VERSION ""

NS_ :

BS_:

BU_: DCDC_2 HV_PDU_1 VCU

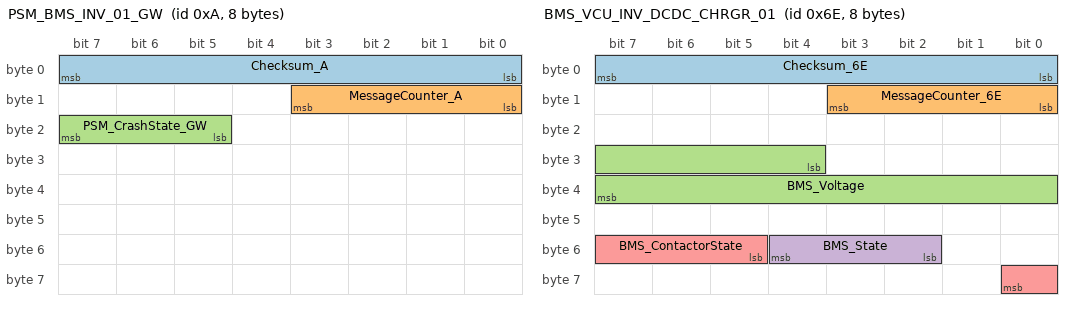
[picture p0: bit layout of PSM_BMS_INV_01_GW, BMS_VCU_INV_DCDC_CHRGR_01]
BO_ 10 PSM_BMS_INV_01_GW: 8 VCU
  SG_ Checksum_A : 0|8@1+ (1,0) [0|255] "NoUnit" DCDC_2
  SG_ MessageCounter_A : 8|4@1+ (1,0) [0|15] "NoUnit" DCDC_2
  SG_ PSM_CrashState_GW : 21|3@1+ (1,0) [0|7] "NoUnit" DCDC_2

BO_ 110 BMS_VCU_INV_DCDC_CHRGR_01: 8 VCU
  SG_ Checksum_6E : 0|8@1+ (1,0) [0|255] "NoUnit" DCDC_2
  SG_ MessageCounter_6E : 8|4@1+ (1,0) [0|15] "NoUnit" DCDC_2
  SG_ BMS_Voltage : 28|12@1+ (0.25,0) [0|1023.25] "V" DCDC_2
  SG_ BMS_State : 50|3@1+ (1,0) [0|7] "NoUnit" DCDC_2
  SG_ BMS_ContactorState : 53|4@1+ (1,0) [0|15] "NoUnit" DCDC_2

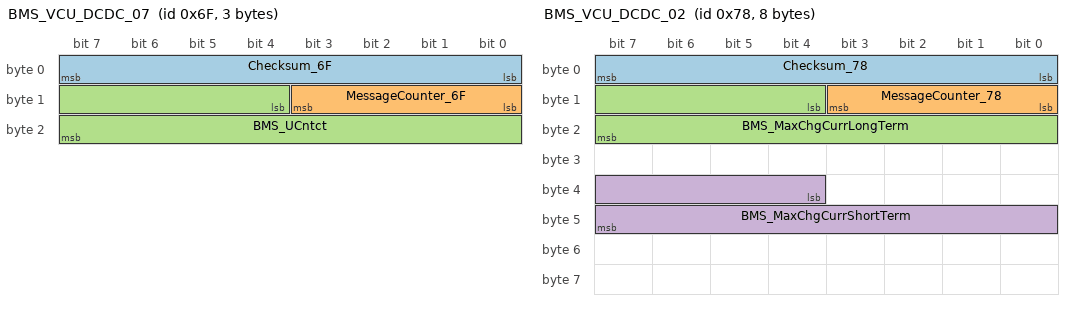
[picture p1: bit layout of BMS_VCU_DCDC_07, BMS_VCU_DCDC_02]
BO_ 111 BMS_VCU_DCDC_07: 3 VCU
  SG_ Checksum_6F : 0|8@1+ (1,0) [0|255] "NoUnit" DCDC_2
  SG_ MessageCounter_6F : 8|4@1+ (1,0) [0|15] "NoUnit" DCDC_2
  SG_ BMS_UCntct : 12|12@1+ (0.25,0) [0|1023.25] "V" DCDC_2

BO_ 120 BMS_VCU_DCDC_02: 8 VCU
  SG_ Checksum_78 : 0|8@1+ (1,0) [0|255] "NoUnit" DCDC_2
  SG_ MessageCounter_78 : 8|4@1+ (1,0) [0|15] "NoUnit" DCDC_2
  SG_ BMS_MaxChgCurrLongTerm : 12|12@1+ (1,0) [0|4094] "A" DCDC_2
  SG_ BMS_MaxChgCurrShortTerm : 36|12@1+ (1,0) [0|4094] "A" DCDC_2

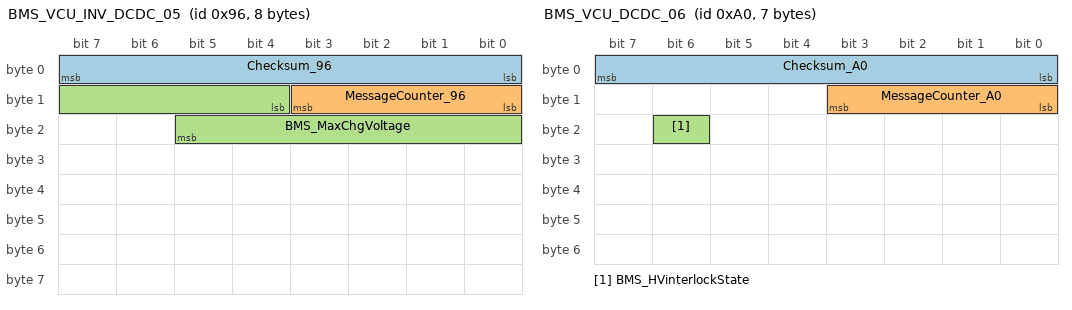
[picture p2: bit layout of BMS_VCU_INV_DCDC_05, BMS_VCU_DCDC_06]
BO_ 150 BMS_VCU_INV_DCDC_05: 8 VCU
  SG_ Checksum_96 : 0|8@1+ (1,0) [0|255] "NoUnit" DCDC_2
  SG_ MessageCounter_96 : 8|4@1+ (1,0) [0|15] "NoUnit" DCDC_2
  SG_ BMS_MaxChgVoltage : 12|10@1+ (1,0) [0|1021] "V" DCDC_2

BO_ 160 BMS_VCU_DCDC_06: 7 VCU
  SG_ Checksum_A0 : 0|8@1+ (1,0) [0|255] "NoUnit" DCDC_2
  SG_ MessageCounter_A0 : 8|4@1+ (1,0) [0|15] "NoUnit" DCDC_2
  SG_ BMS_HVinterlockState : 22|1@1+ (1,0) [0|1] "NoUnit" DCDC_2

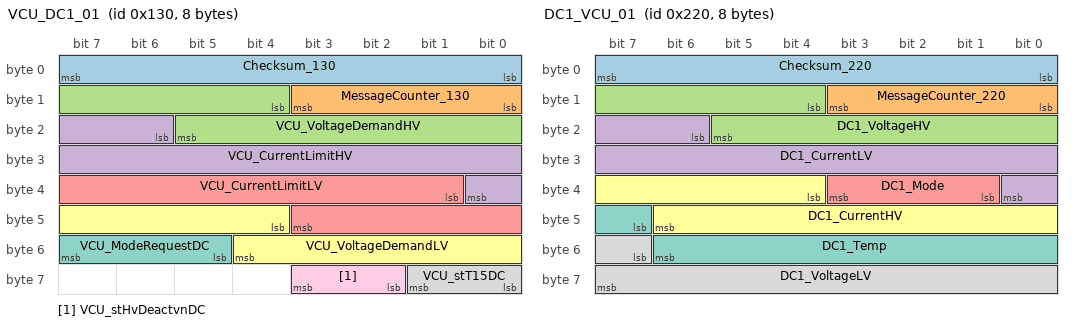
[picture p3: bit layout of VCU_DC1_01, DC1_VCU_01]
BO_ 304 VCU_DC1_01: 8 VCU
  SG_ Checksum_130 : 0|8@1+ (1,0) [0|255] "NoUnit" DCDC_2
  SG_ MessageCounter_130 : 8|4@1+ (1,0) [0|15] "NoUnit" DCDC_2
  SG_ VCU_VoltageDemandHV : 12|10@1+ (1,0) [0|1021] "V" DCDC_2
  SG_ VCU_CurrentLimitHV : 22|11@1+ (0.0625,-64) [-64|63.8125] "A" DCDC_2
  SG_ VCU_CurrentLimitLV : 33|11@1+ (1,-1023) [-1023|1022] "A" DCDC_2
  SG_ VCU_VoltageDemandLV : 44|9@1+ (0.125,0) [0|63.625] "V" DCDC_2
  SG_ VCU_ModeRequestDC : 53|3@1+ (1,0) [0|7] "NoUnit" DCDC_2
  SG_ VCU_stT15DC : 56|2@1+ (1,0) [0|1] "NoUnit" DCDC_2
  SG_ VCU_stHvDeactvnDC : 58|2@1+ (1,0) [0|3] "NoUnit" DCDC_2

BO_ 514 XCP_Response_Ivt: 8 HV_PDU_1
  SG_ XCP_Buffer_TxIvt : 0|64@1- (1,0) [0|0] "NoUnit" VCU

BO_ 544 DC1_VCU_01: 8 DCDC_2
  SG_ Checksum_220 : 0|8@1+ (1,0) [0|255] "NoUnit" VCU
  SG_ MessageCounter_220 : 8|4@1+ (1,0) [0|15] "NoUnit" VCU
  SG_ DC1_VoltageHV : 12|10@1+ (1,0) [0|1021] "V" VCU
  SG_ DC1_CurrentLV : 22|11@1+ (1,-1023) [-1023|1022] "A" VCU
  SG_ DC1_Mode : 33|3@1+ (1,0) [0|7] "NoUnit" VCU
  SG_ DC1_CurrentHV : 36|11@1+ (0.0625,-63.90625) [-63.90625|63.90625] "A" VCU
  SG_ DC1_Temp : 47|8@1+ (1,-40) [-40|213] "°C" VCU
  SG_ DC1_VoltageLV : 55|9@1+ (0.125,0) [0|63.625] "V" VCU

BO_ 770 UDS_Response_Ivt: 8 HV_PDU_1
  SG_ UDS_Buffer_TxIvt : 0|64@1- (1,0) [0|0] "NoUnit" VCU

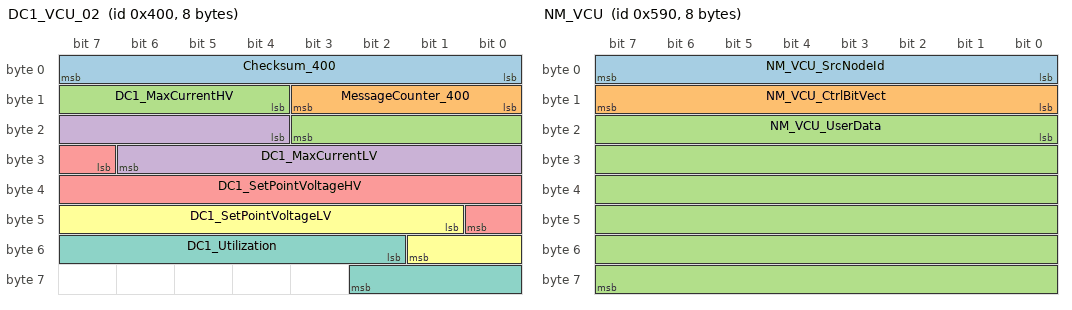
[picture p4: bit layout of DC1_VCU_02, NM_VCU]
BO_ 1024 DC1_VCU_02: 8 DCDC_2
  SG_ Checksum_400 : 0|8@1+ (1,0) [0|255] "NoUnit" VCU
  SG_ MessageCounter_400 : 8|4@1+ (1,0) [0|15] "NoUnit" VCU
  SG_ DC1_MaxCurrentHV : 12|8@1+ (0.25,0) [0|63.75] "A" VCU
  SG_ DC1_MaxCurrentLV : 20|11@1+ (1,-1023) [-1023|1024] "A" VCU
  SG_ DC1_SetPointVoltageHV : 31|10@1+ (1,0) [0|1023] "V" VCU
  SG_ DC1_SetPointVoltageLV : 41|9@1+ (0.125,0) [0|63.875] "V" VCU
  SG_ DC1_Utilization : 50|9@1+ (0.25,0) [0|127.75] "%" VCU

BO_ 1040 DC1_VCU_03: 4 DCDC_2
  SG_ Checksum_410 : 0|8@1+ (1,0) [0|255] "NoUnit" VCU
  SG_ MessageCounter_410 : 8|4@1+ (1,0) [0|15] "NoUnit" VCU
  SG_ DC1_bDernUndrUdcLv : 12|1@1+ (1,0) [0|1] "NoUnit" VCU
  SG_ DC1_bDernOvrUdcLv : 13|1@1+ (1,0) [0|1] "NoUnit" VCU
  SG_ DC1_bDernUndrUdcHv : 14|1@1+ (1,0) [0|1] "NoUnit" VCU
  SG_ DC1_bDernOvrUdcHv : 15|1@1+ (1,0) [0|1] "NoUnit" VCU
  SG_ DC1_bDernTemp_DCDC : 18|1@1+ (1,0) [0|1] "NoUnit" VCU
  SG_ DC1_ErrLimitedPerformance : 19|1@1+ (1,0) [0|1] "NoUnit" VCU
  SG_ DC1_bErrVltg : 20|1@1+ (1,0) [0|1] "NoUnit" VCU
  SG_ DC1_ErrShtOff : 21|1@1+ (1,0) [0|1] "NoUnit" VCU
  SG_ DC1_bErrCrashDetd : 22|1@1+ (1,0) [0|1] "NoUnit" VCU
  SG_ DC1_bErrLvBattOutOfRng : 23|1@1+ (1,0) [0|1] "NoUnit" VCU
  SG_ DC1_bErrHvLineOutOfRng : 24|1@1+ (1,0) [0|1] "NoUnit" VCU
  SG_ DC1_bErrHvIllegalCurrent : 25|1@1+ (1,0) [0|1] "NoUnit" VCU
  SG_ DC1_bErrHvSpNotReachedTimeout : 26|1@1+ (1,0) [0|1] "NoUnit" VCU
  SG_ DC1_bErrCanMsg : 27|1@1+ (1,0) [0|1] "NoUnit" VCU
  SG_ DC1_bPrecCmpl : 28|1@1+ (1,0) [0|1] "NoUnit" VCU
  SG_ DC1_bReqMIL : 29|1@1+ (1,0) [0|1] "NoUnit" VCU
  SG_ DC1_stT30c : 30|2@1+ (1,0) [0|3] "NoUnit" VCU

BO_ 1424 NM_VCU: 8 VCU
  SG_ NM_VCU_SrcNodeId : 0|8@1+ (1,0) [0|255] "NoUnit" DCDC_2
  SG_ NM_VCU_CtrlBitVect : 8|8@1+ (1,0) [0|255] "NoUnit" DCDC_2
  SG_ NM_VCU_UserData : 16|48@1+ (1,0) [0|0] "NoUnit" DCDC_2

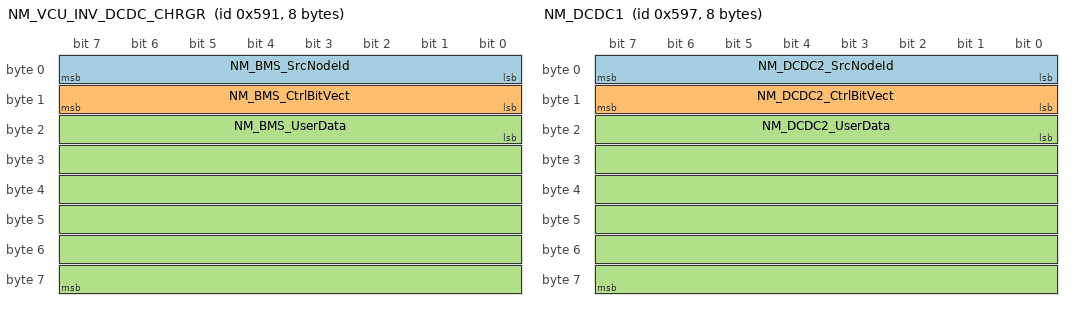
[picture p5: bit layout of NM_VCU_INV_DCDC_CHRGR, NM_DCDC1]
BO_ 1425 NM_VCU_INV_DCDC_CHRGR: 8 VCU
  SG_ NM_BMS_SrcNodeId : 0|8@1+ (1,0) [0|255] "NoUnit" DCDC_2
  SG_ NM_BMS_CtrlBitVect : 8|8@1+ (1,0) [0|255] "NoUnit" DCDC_2
  SG_ NM_BMS_UserData : 16|48@1+ (1,0) [0|0] "NoUnit" DCDC_2

BO_ 1431 NM_DCDC1: 8 DCDC_2
  SG_ NM_DCDC2_SrcNodeId : 0|8@1+ (1,0) [0|255] "NoUnit" VCU
  SG_ NM_DCDC2_CtrlBitVect : 8|8@1+ (1,0) [0|255] "NoUnit" VCU
  SG_ NM_DCDC2_UserData : 16|48@1+ (1,0) [0|0] "NoUnit" VCU

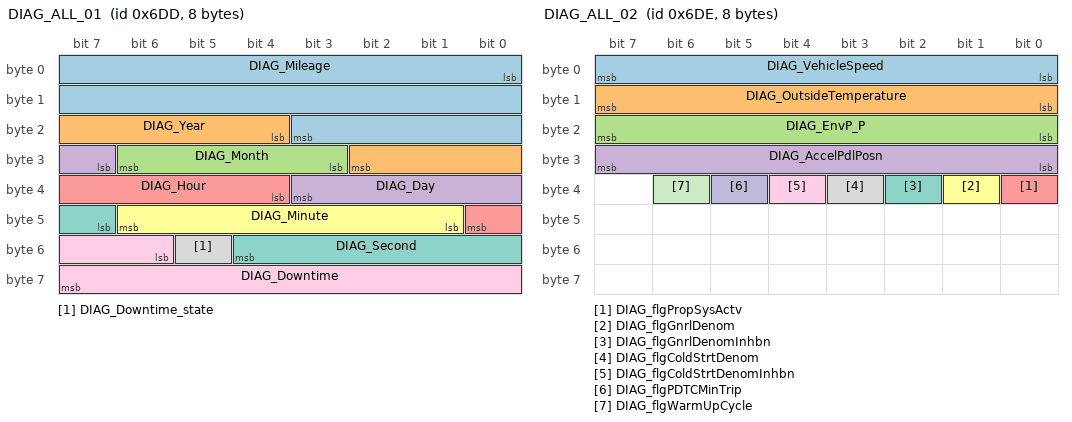
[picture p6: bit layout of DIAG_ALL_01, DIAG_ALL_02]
BO_ 1757 DIAG_ALL_01: 8 VCU
  SG_ DIAG_Mileage : 0|20@1+ (1,0) [0|1048575] "Km" DCDC_2
  SG_ DIAG_Year : 20|7@1+ (1,2000) [2000|2127] "year" DCDC_2
  SG_ DIAG_Month : 27|4@1+ (1,0) [1|12] "month" DCDC_2
  SG_ DIAG_Day : 31|5@1+ (1,0) [1|31] "day" DCDC_2
  SG_ DIAG_Hour : 36|5@1+ (1,0) [0|23] "h" DCDC_2
  SG_ DIAG_Minute : 41|6@1+ (1,0) [0|59] "NoUnit" DCDC_2
  SG_ DIAG_Second : 47|6@1+ (1,0) [0|59] "s" DCDC_2
  SG_ DIAG_Downtime_state : 53|1@1+ (1,0) [0|1] "NoUnit" DCDC_2
  SG_ DIAG_Downtime : 54|10@1+ (32,0) [0|32736] "s" DCDC_2

BO_ 1758 DIAG_ALL_02: 8 VCU
  SG_ DIAG_VehicleSpeed : 0|8@1+ (1,0) [0|255] "KMPH" DCDC_2
  SG_ DIAG_OutsideTemperature : 8|8@1+ (1,-40) [-40|213] "°C" DCDC_2
  SG_ DIAG_EnvP_P : 16|8@1+ (7.8,0) [0|1973.4] "hPa" DCDC_2
  SG_ DIAG_AccelPdlPosn : 24|8@1+ (0.5,0) [0|100] "%" DCDC_2
  SG_ DIAG_flgPropSysActv : 32|1@1+ (1,0) [0|1] "NoUnit" DCDC_2
  SG_ DIAG_flgGnrlDenom : 33|1@1+ (1,0) [0|1] "NoUnit" DCDC_2
  SG_ DIAG_flgGnrlDenomInhbn : 34|1@1+ (1,0) [0|1] "NoUnit" DCDC_2
  SG_ DIAG_flgColdStrtDenom : 35|1@1+ (1,0) [0|1] "NoUnit" DCDC_2
  SG_ DIAG_flgColdStrtDenomInhbn : 36|1@1+ (1,0) [0|1] "NoUnit" DCDC_2
  SG_ DIAG_flgPDTCMinTrip : 37|1@1+ (1,0) [0|1] "NoUnit" DCDC_2
  SG_ DIAG_flgWarmUpCycle : 38|1@1+ (1,0) [0|1] "NoUnit" DCDC_2

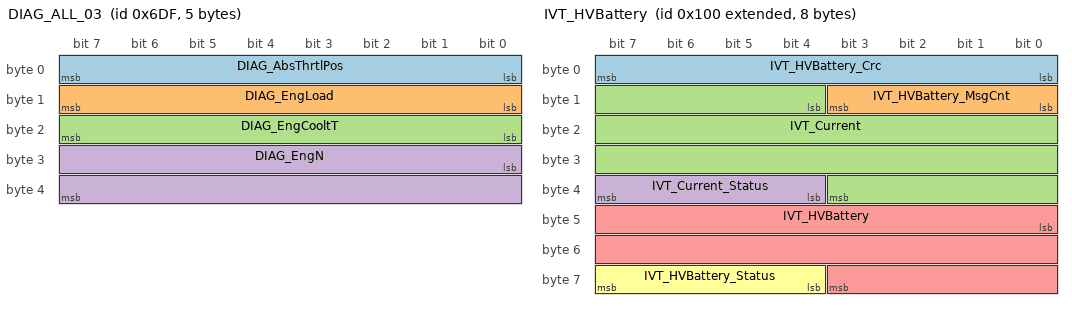
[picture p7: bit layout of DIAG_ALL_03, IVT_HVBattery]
BO_ 1759 DIAG_ALL_03: 5 VCU
  SG_ DIAG_AbsThrtlPos : 0|8@1+ (0.392157,0) [0|100.000035] "%" DCDC_2
  SG_ DIAG_EngLoad : 8|8@1+ (0.392157,0) [0|100.000035] "%" DCDC_2
  SG_ DIAG_EngCooltT : 16|8@1+ (1,-40) [-40|215] "°C" DCDC_2
  SG_ DIAG_EngN : 24|16@1+ (0.25,0) [0|16383.25] "1/min" DCDC_2

BO_ 1792 DIAG_REQUEST_FUNC: 8 VCU
  SG_ N_PDU_RQ_FUNC : 0|64@1+ (1,0) [0|0] "NoUnit" DCDC_2

BO_ 2015 DIAG_REQUEST_OBD: 8 VCU
  SG_ N_PDU_RQ_OBD : 0|64@1+ (1,0) [0|0] "NoUnit" DCDC_2

BO_ 2019 DIAG_REQUEST_DC1: 8 VCU
  SG_ N_PDU_RQ_DC1 : 0|64@1+ (1,0) [0|0] "NoUnit" DCDC_2

BO_ 2027 DIAG_RESPONSE_DC1: 8 DCDC_2
  SG_ N_PDU_RESP_DC2 : 0|64@1+ (1,0) [0|1.84467440737096E+019] "NoUnit" VCU

BO_ 2147483904 IVT_HVBattery: 8 HV_PDU_1
  SG_ IVT_HVBattery_Crc : 0|8@1+ (1,0) [0|255] "NoUnit" VCU
  SG_ IVT_HVBattery_MsgCnt : 8|4@1+ (1,0) [0|15] "NoUnit" VCU
  SG_ IVT_Current : 12|24@1+ (0.002,-16777.216) [-16777.216|16777.214] "A" VCU
  SG_ IVT_Current_Status : 36|4@1+ (1,0) [0|15] "NoUnit" VCU
  SG_ IVT_HVBattery : 40|20@1+ (0.004,-2097.152) [-2097.152|2097.148] "V" VCU
  SG_ IVT_HVBattery_Status : 60|4@1+ (1,0) [0|15] "NoUnit" VCU

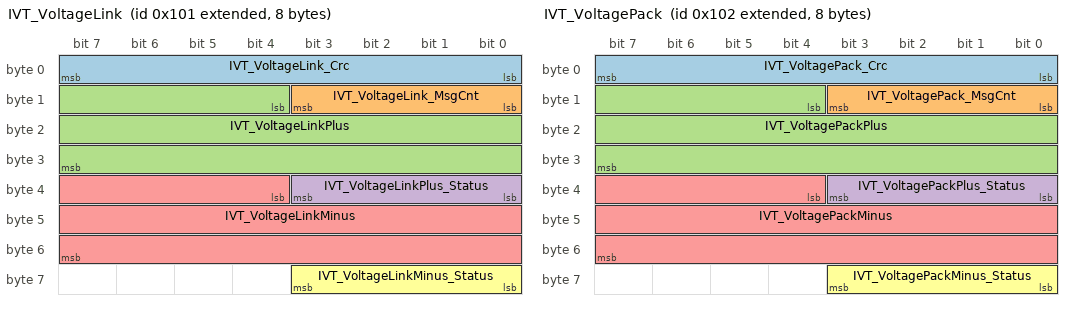
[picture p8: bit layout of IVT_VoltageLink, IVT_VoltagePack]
BO_ 2147483905 IVT_VoltageLink: 8 HV_PDU_1
  SG_ IVT_VoltageLink_Crc : 0|8@1+ (1,0) [0|255] "NoUnit" VCU
  SG_ IVT_VoltageLink_MsgCnt : 8|4@1+ (1,0) [0|15] "NoUnit" VCU
  SG_ IVT_VoltageLinkPlus : 12|20@1+ (0.004,-2097.152) [-2097.152|2097.148] "V" VCU
  SG_ IVT_VoltageLinkPlus_Status : 32|4@1+ (1,0) [0|15] "NoUnit" VCU
  SG_ IVT_VoltageLinkMinus : 36|20@1+ (0.004,-2097.152) [-2097.152|2097.148] "V" VCU
  SG_ IVT_VoltageLinkMinus_Status : 56|4@1+ (1,0) [0|15] "NoUnit" VCU

BO_ 2147483906 IVT_VoltagePack: 8 HV_PDU_1
  SG_ IVT_VoltagePack_Crc : 0|8@1+ (1,0) [0|255] "NoUnit" VCU
  SG_ IVT_VoltagePack_MsgCnt : 8|4@1+ (1,0) [0|15] "NoUnit" VCU
  SG_ IVT_VoltagePackPlus : 12|20@1+ (0.004,-2097.152) [-2097.152|2097.148] "V" VCU
  SG_ IVT_VoltagePackPlus_Status : 32|4@1+ (1,0) [0|15] "NoUnit" VCU
  SG_ IVT_VoltagePackMinus : 36|20@1+ (0.004,-2097.152) [-2097.152|2097.148] "V" VCU
  SG_ IVT_VoltagePackMinus_Status : 56|4@1+ (1,0) [0|15] "NoUnit" VCU

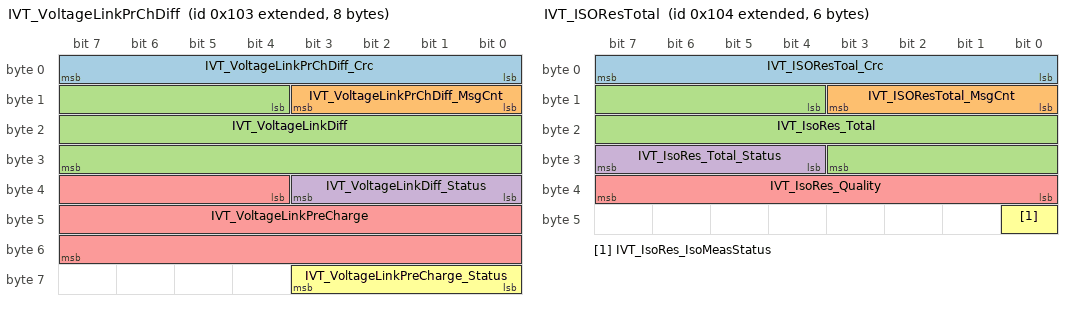
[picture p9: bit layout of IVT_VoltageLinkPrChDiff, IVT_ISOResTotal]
BO_ 2147483907 IVT_VoltageLinkPrChDiff: 8 HV_PDU_1
  SG_ IVT_VoltageLinkPrChDiff_Crc : 0|8@1+ (1,0) [0|255] "NoUnit" VCU
  SG_ IVT_VoltageLinkPrChDiff_MsgCnt : 8|4@1+ (1,0) [0|15] "NoUnit" VCU
  SG_ IVT_VoltageLinkDiff : 12|20@1+ (0.004,-2097.152) [-2097.152|2097.148] "V" VCU
  SG_ IVT_VoltageLinkDiff_Status : 32|4@1+ (1,0) [0|15] "NoUnit" VCU
  SG_ IVT_VoltageLinkPreCharge : 36|20@1+ (0.004,-2097.152) [-2097.152|2097.148] "V" VCU
  SG_ IVT_VoltageLinkPreCharge_Status : 56|4@1+ (1,0) [0|15] "NoUnit" VCU

BO_ 2147483908 IVT_ISOResTotal: 6 HV_PDU_1
  SG_ IVT_ISOResToal_Crc : 0|8@1+ (1,0) [0|255] "NoUnit" VCU
  SG_ IVT_ISOResTotal_MsgCnt : 8|4@1+ (1,0) [0|15] "NoUnit" VCU
  SG_ IVT_IsoRes_Total : 12|16@1+ (1,0) [0|65535] "kOhm" VCU
  SG_ IVT_IsoRes_Total_Status : 28|4@1+ (1,0) [0|15] "NoUnit" VCU
  SG_ IVT_IsoRes_Quality : 32|8@1+ (1,0) [0|100] "%" VCU
  SG_ IVT_IsoRes_IsoMeasStatus : 40|1@1+ (1,0) [0|1] "NoUnit" VCU

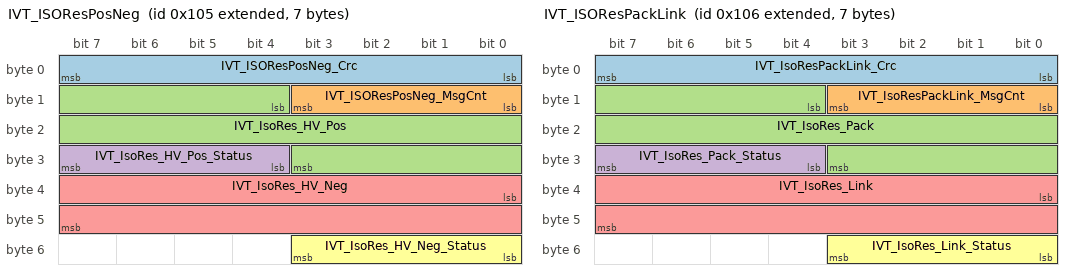
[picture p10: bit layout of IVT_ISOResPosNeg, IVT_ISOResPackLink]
BO_ 2147483909 IVT_ISOResPosNeg: 7 HV_PDU_1
  SG_ IVT_ISOResPosNeg_Crc : 0|8@1+ (1,0) [0|255] "NoUnit" VCU
  SG_ IVT_ISOResPosNeg_MsgCnt : 8|4@1+ (1,0) [0|15] "NoUnit" VCU
  SG_ IVT_IsoRes_HV_Pos : 12|16@1+ (1,0) [0|65535] "kOhm" VCU
  SG_ IVT_IsoRes_HV_Pos_Status : 28|4@1+ (1,0) [0|15] "NoUnit" VCU
  SG_ IVT_IsoRes_HV_Neg : 32|16@1+ (1,0) [0|65535] "kOhm" VCU
  SG_ IVT_IsoRes_HV_Neg_Status : 48|4@1+ (1,0) [0|15] "NoUnit" VCU

BO_ 2147483910 IVT_ISOResPackLink: 7 HV_PDU_1
  SG_ IVT_IsoResPackLink_Crc : 0|8@1+ (1,0) [0|255] "NoUnit" VCU
  SG_ IVT_IsoResPackLink_MsgCnt : 8|4@1+ (1,0) [0|15] "NoUnit" VCU
  SG_ IVT_IsoRes_Pack : 12|16@1+ (1,0) [0|65535] "kOhm" VCU
  SG_ IVT_IsoRes_Pack_Status : 28|4@1+ (1,0) [0|15] "NoUnit" VCU
  SG_ IVT_IsoRes_Link : 32|16@1+ (1,0) [0|65535] "kOhm" VCU
  SG_ IVT_IsoRes_Link_Status : 48|4@1+ (1,0) [0|15] "NoUnit" VCU

BO_ 2147483911 IVT_Temperature: 3 HV_PDU_1
  SG_ IVT_ShuntTemp : 12|8@1+ (1,-50) [-50|205] "°C" VCU
  SG_ IVT_ShuntTemp_Status : 20|4@1+ (1,0) [0|15] "NoUnit" VCU

CM_ BU_ DCDC_2 "The DCDC Converter is used for converting the HV (400V) Battery energy to LV (12V) energy for driving LV loads and charging the 12V LV Battery. The DCDC converter provides information about various parameters like High Side Voltage, Low Side Voltage, High Side Current, Low Side Current etc. to vehicle over CAN channel. ";
CM_ BU_ HV_PDU_1 "The High Voltage Power Distribution Unit ( HV PDU) shall be connected to HV Batteries. The HV PDU shall distribute the HV power through various ports to different HV loads. The HV PDU shall be connected to HV BMS over private CAN channels. The HV PDU shall receive the status from HV BMS and shall communicate the consolidated status to vehicle ECUs over powerrtain CAN.";
CM_ BU_ VCU "The Vehicle Control Unit (VCU) is a supervisory controller which covers features such as propulsion system, HV energy management, thermal management and LV energy management. The primary responsibility of VCU is to determine acceleration and deceleration functions as per request in automated/manual driving. VCU monitors the HV components and provide overall status to all other Controllers on CAN BUS. VCU monitors and control the operation of LV powernet components. VCU is also responsible for determining and communicate the thermal priority to Thermal management system among powertrain components, Battery, SDS and cabin. As supervisory controller VCU is responsible for monitoring the failures in Propulsion system, HV system, Thermal system and provide the status to vehicle fault manager ";
CM_ BO_ 10 "PSM ? Crash level information

Versionsinfo_RB_PF_EV_CAN: Rev 3.20";
CM_ BO_ 110 "High-Voltage battery related information

Versionsinfo_RB_PF_EV_CAN: Rev 3.20";
CM_ BO_ 111 "High-Voltage battery related information";
CM_ BO_ 120 "High-Voltage battery Current Charging and Discharging information";
CM_ BO_ 150 "High-Voltage battery Voltage Charging and Discharging information";
CM_ BO_ 160 "BMS - Interlock, pump related info Frame";
CM_ BO_ 304 "Inverter1 DCDC Control Frame";
CM_ BO_ 544 "Inverter1 DCDC Information Frame - Present Status

Versionsinfo_RB_PF_EV_CAN: Rev 3.20";
CM_ BO_ 770 "UDS response message";
CM_ BO_ 1024 "Inverter1 DCDC Information Frame - Current and Voltage Status";
CM_ BO_ 1040 "Inverter1 DCDC Information Frame - Limits / Error / Derating information";
CM_ BO_ 1424 "Network Management Message from VCU ECU";
CM_ BO_ 1425 "Network Management Message from BMS ECU";
CM_ BO_ 1431 "Network Management Message from Inverter1 ECU";
CM_ BO_ 1757 "Real Time, Mileage & Vehicle Down time information";
CM_ BO_ 1758 "various enviroment information for OBD";
CM_ BO_ 1759 "various enviroment information for OBD in HEV (optional)";
CM_ BO_ 1792 "Diagnostic Message used by Tester

Versionsinfo_RB_PF_EV_CAN: Rev 3.20";
CM_ BO_ 2015 "Diagnostic Message used by Tester";
CM_ BO_ 2019 "Diagnostic Message used by Tester in Inverter1";
CM_ BO_ 2027 "Diagnostic Message used by Tester in Inverter1";
CM_ BO_ 2147483904 "E2E protected message containing the measured current and battery voltage.";
CM_ BO_ 2147483905 "E2E protected message containing the measured link side voltages.";
CM_ BO_ 2147483906 "E2E protected message containing the measured pack side voltages.";
CM_ BO_ 2147483908 "E2E protected message containing the measured total isolation resistance and quality.";
CM_ BO_ 2147483909 "E2E protected message containing the measured isoaltion resistance for positive and negative side.";
CM_ BO_ 2147483910 "E2E protected message containing the measured isoaltion resistance for pack and link side.";
CM_ BO_ 2147483911 "Message containing the shunt temperature value.";
CM_ SG_ 10 Checksum_A "Checksum signal, computation according to Autosar E2E communication protection profile 2";
CM_ SG_ 10 MessageCounter_A "Message counter signal, computation according to Autosar E2E communication protection profile 2";
CM_ SG_ 10 PSM_CrashState_GW "Crash level";
CM_ SG_ 110 Checksum_6E "Checksum signal, computation according to Autosar E2E communication protection profile 2";
CM_ SG_ 110 MessageCounter_6E "Message counter signal, computation according to Autosar E2E communication protection profile 2";
CM_ SG_ 110 BMS_Voltage "Voltage of the electric energy storage";
CM_ SG_ 110 BMS_State "State of electric energy storage";
CM_ SG_ 110 BMS_ContactorState "State of the HV contactors";
CM_ SG_ 111 Checksum_6F "Checksum signal, computation according to Autosar E2E communication protection profile 2";
CM_ SG_ 111 MessageCounter_6F "Message counter signal, computation according to Autosar E2E communication protection profile 2";
CM_ SG_ 111 BMS_UCntct "contactor output voltage of the electric energy storage";
CM_ SG_ 120 Checksum_78 "Checksum signal, computation according to Autosar E2E communication protection profile 2";
CM_ SG_ 120 MessageCounter_78 "Message counter signal, computation according to Autosar E2E communication protection profile 2";
CM_ SG_ 120 BMS_MaxChgCurrLongTerm "Maximum charging long term current, usage including determination of charging current for AC and DC charging.";
CM_ SG_ 120 BMS_MaxChgCurrShortTerm "Maximum charging short term current";
CM_ SG_ 150 Checksum_96 "Checksum signal, computation according to Autosar E2E communication protection profile 2";
CM_ SG_ 150 MessageCounter_96 "Message counter signal, computation according to Autosar E2E communication protection profile 2";
CM_ SG_ 150 BMS_MaxChgVoltage "ultimate limit of maximum charging voltage for HV battery protection";
CM_ SG_ 160 Checksum_A0 "Checksum signal, computation according to Autosar E2E communication protection profile 2";
CM_ SG_ 160 MessageCounter_A0 "Message counter signal, computation according to Autosar E2E communication protection profile 2";
CM_ SG_ 160 BMS_HVinterlockState "HV interlock state";
CM_ SG_ 304 Checksum_130 "Checksum signal, computation according to Autosar E2E communication protection profile 2";
CM_ SG_ 304 MessageCounter_130 "Message counter signal, computation according to Autosar E2E communication protection profile 2";
CM_ SG_ 304 VCU_VoltageDemandHV "Desired voltage of the DCDC converter HV side (boost mode)";
CM_ SG_ 304 VCU_CurrentLimitHV "Limit for HV- current of DC/DC converter (pos: into DCDC | neg: unused)";
CM_ SG_ 304 VCU_CurrentLimitLV "Limit for LV- current of DC/DC converter (pos: into LV power net | neg: into DCDC)";
CM_ SG_ 304 VCU_VoltageDemandLV "Desired voltage of the DCDC converter LV side (buck mode)";
CM_ SG_ 304 VCU_ModeRequestDC "Requested mode of the DCDC converter";
CM_ SG_ 304 VCU_stT15DC "Terminal 15 (T15) state";
CM_ SG_ 304 VCU_stHvDeactvnDC "HV deactivation signal (e.g. for service conditions)";
CM_ SG_ 544 Checksum_220 "Checksum signal, computation according to Autosar E2E communication protection profile 2";
CM_ SG_ 544 MessageCounter_220 "Message counter signal, computation according to Autosar E2E communication protection profile 2";
CM_ SG_ 544 DC1_VoltageHV "Voltage at high voltage side";
CM_ SG_ 544 DC1_CurrentLV "Current on low voltage side (pos: into LV powernet  | neg: into DCDC)";
CM_ SG_ 544 DC1_Mode "State DC/DC converter";
CM_ SG_ 544 DC1_CurrentHV "Current at high voltage side (pos: into DCDC | neg: into HV powernet)";
CM_ SG_ 544 DC1_Temp "Temperature of DCDC";
CM_ SG_ 544 DC1_VoltageLV "Voltage on low voltage side";
CM_ SG_ 770 UDS_Buffer_TxIvt "UDS response signal";
CM_ SG_ 1024 Checksum_400 "Checksum signal, computation according to Autosar E2E communication protection profile 2";
CM_ SG_ 1024 MessageCounter_400 "Message counter signal, computation according to Autosar E2E communication protection profile 2";
CM_ SG_ 1024 DC1_MaxCurrentHV "Maximal possible current at high voltage side (pos: into DCDC | neg: into HV power net)";
CM_ SG_ 1024 DC1_MaxCurrentLV "Maximum possible current on low voltage side (pos: into LV power net | neg: unused)";
CM_ SG_ 1024 DC1_SetPointVoltageHV "Present set point of high voltage (boost mode)";
CM_ SG_ 1024 DC1_SetPointVoltageLV "Present set point of low voltage (buck mode)";
CM_ SG_ 1024 DC1_Utilization "Utilization rate";
CM_ SG_ 1040 Checksum_410 "Checksum signal, computation according to Autosar E2E communication protection profile 2";
CM_ SG_ 1040 MessageCounter_410 "Message counter signal, computation according to Autosar E2E communication protection profile 2";
CM_ SG_ 1040 DC1_bDernUndrUdcLv "Derating because of Low Voltage at LV";
CM_ SG_ 1040 DC1_bDernOvrUdcLv "Derating because of error high voltage at LV";
CM_ SG_ 1040 DC1_bDernUndrUdcHv "Derating because of error low voltage at HV";
CM_ SG_ 1040 DC1_bDernOvrUdcHv "Derating because of high voltage at HV";
CM_ SG_ 1040 DC1_bDernTemp_DCDC "Derating because of overtemperature DCDC";
CM_ SG_ 1040 DC1_ErrLimitedPerformance "limited performance of DCDC";
CM_ SG_ 1040 DC1_bErrVltg "shutdown because of Over/Undervoltage at I/O side";
CM_ SG_ 1040 DC1_ErrShtOff "Derating because of DCDC shutdown";
CM_ SG_ 1040 DC1_bErrCrashDetd "External fault: detected light/soft or strong/hard Crash";
CM_ SG_ 1040 DC1_bErrLvBattOutOfRng "External fault: LV battery is detected out of range";
CM_ SG_ 1040 DC1_bErrHvLineOutOfRng "External fault: HV line out of range";
CM_ SG_ 1040 DC1_bErrHvIllegalCurrent "External fault: Recognition of illegal HV current";
CM_ SG_ 1040 DC1_bErrHvSpNotReachedTimeout "External fault: Desired HV Line voltage not reached within time";
CM_ SG_ 1040 DC1_bErrCanMsg "External fault: CAN error (e.g. frame timeout, global timeout, message corruption, alive counter)";
CM_ SG_ 1040 DC1_bPrecCmpl "Status of precharging operation";
CM_ SG_ 1040 DC1_bReqMIL "MIL (Malfunction Indicator Lamp) request by DCDC1";
CM_ SG_ 1040 DC1_stT30c "Terminal 30c (T30c) state: permanent supply, can be interrupted by crash (non-reversible) or service disconnect";
CM_ SG_ 1424 NM_VCU_SrcNodeId "VCU Network Management Node id";
CM_ SG_ 1424 NM_VCU_CtrlBitVect "Reserved for AUTOSAR NM. Currently unused.";
CM_ SG_ 1424 NM_VCU_UserData "VCU Network Management User Data";
CM_ SG_ 1425 NM_BMS_SrcNodeId "Reserved for AUTOSAR NM. Currently unused.";
CM_ SG_ 1425 NM_BMS_CtrlBitVect "Reserved for AUTOSAR NM. Currently unused.";
CM_ SG_ 1425 NM_BMS_UserData "BMS Network Management User Data";
CM_ SG_ 1431 NM_DCDC2_SrcNodeId "0: Inverter0
1: Inverter1
2: Inverter2";
CM_ SG_ 1431 NM_DCDC2_CtrlBitVect "Reserved for AUTOSAR NM. Currently unused.";
CM_ SG_ 1431 NM_DCDC2_UserData "Inverter1 Network Management User Data";
CM_ SG_ 1757 DIAG_Mileage "Mileage";
CM_ SG_ 1757 DIAG_Year "year";
CM_ SG_ 1757 DIAG_Month "Month";
CM_ SG_ 1757 DIAG_Day "Day";
CM_ SG_ 1757 DIAG_Hour "Hour";
CM_ SG_ 1757 DIAG_Minute "Minute";
CM_ SG_ 1757 DIAG_Second "Second";
CM_ SG_ 1757 DIAG_Downtime_state "state of transmitted signal Downtime";
CM_ SG_ 1757 DIAG_Downtime "Calculated Downtime of System (car sleep)";
CM_ SG_ 1758 DIAG_VehicleSpeed "Overall Vehicle speed";
CM_ SG_ 1758 DIAG_OutsideTemperature "outside temperature";
CM_ SG_ 1758 DIAG_EnvP_P "Environment air pressure";
CM_ SG_ 1758 DIAG_AccelPdlPosn "Accelerator Pedal Position";
CM_ SG_ 1758 DIAG_flgPropSysActv "OBD propulsion system active (replaces OBD driving cycle)";
CM_ SG_ 1758 DIAG_flgGnrlDenom "OBD general denominator";
CM_ SG_ 1758 DIAG_flgGnrlDenomInhbn "OBD general denominator inhibited due to error";
CM_ SG_ 1758 DIAG_flgColdStrtDenom "OBD cold start denominator";
CM_ SG_ 1758 DIAG_flgColdStrtDenomInhbn "OBD cold start denominator inhibited due to error";
CM_ SG_ 1758 DIAG_flgPDTCMinTrip "OBD PDTC erase conditions - minimum trip";
CM_ SG_ 1758 DIAG_flgWarmUpCycle "OBD warmup cycle classic";
CM_ SG_ 1759 DIAG_AbsThrtlPos "PID$11: Absolute Throttle Position";
CM_ SG_ 1759 DIAG_EngLoad "PID$04: Calculated load value";
CM_ SG_ 1759 DIAG_EngCooltT "PID$05: engine coolant temperature";
CM_ SG_ 1759 DIAG_EngN "PID$0C: engine speed";
CM_ SG_ 1792 N_PDU_RQ_FUNC "This signal is used for diagnostic purposes";
CM_ SG_ 2015 N_PDU_RQ_OBD "This signal is used for diagnostic purposes";
CM_ SG_ 2019 N_PDU_RQ_DC1 "This signal is used for diagnostic purposes";
CM_ SG_ 2027 N_PDU_RESP_DC2 "This signal is used for diagnostic purposes";
CM_ SG_ 2147483904 IVT_Current "Measured current value";
CM_ SG_ 2147483904 IVT_Current_Status "Status of current measurement";
CM_ SG_ 2147483904 IVT_HVBattery "Measured battery voltage";
CM_ SG_ 2147483904 IVT_HVBattery_Status "Status of measured battery voltage";
CM_ SG_ 2147483908 IVT_IsoRes_Total "Total isolation resistance";
CM_ SG_ 2147483908 IVT_IsoRes_Total_Status "Status of total isolation resistance";
CM_ SG_ 2147483908 IVT_IsoRes_Quality "Quality estimation for the isolation resistance measurement";
CM_ SG_ 2147483908 IVT_IsoRes_IsoMeasStatus "Total isolation resistance";
CM_ SG_ 2147483909 IVT_IsoRes_HV_Pos "Isolation resistance on HV+ line";
CM_ SG_ 2147483909 IVT_IsoRes_HV_Pos_Status "Status of isolation resistance on HV+ line";
CM_ SG_ 2147483909 IVT_IsoRes_HV_Neg "Isolation resistance on HV- line";
CM_ SG_ 2147483909 IVT_IsoRes_HV_Neg_Status "Status of isolation resistance on HV- line";
CM_ SG_ 2147483910 IVT_IsoRes_Pack "Isolation resistance on pack side";
CM_ SG_ 2147483910 IVT_IsoRes_Pack_Status "Status of isolation resistance on pack side";
CM_ SG_ 2147483910 IVT_IsoRes_Link "Isolation resistance on link side";
CM_ SG_ 2147483910 IVT_IsoRes_Link_Status "Status of isolation resistance measurement on link side";
CM_ SG_ 2147483911 IVT_ShuntTemp "Measured temperature of the shunt";
CM_ SG_ 2147483911 IVT_ShuntTemp_Status "Status of shunt temperature measurement";

BA_DEF_  "SigType" ENUM "Default","Range","RangeSigned","ASCII","Discrete","Control","ReferencePGN","DTC","StringDelimiter","StringLength","StringLengthControl";
BA_DEF_ SG_  "ASIL" ENUM "ASIL A","ASIL B","ASIL C","ASIL D","NA","QM";
BA_DEF_ BO_  "ASILLevel" ENUM "ASIL A","ASIL B","ASIL C","ASIL D","NA","QM";
BA_DEF_ SG_  "GenSigSendType" ENUM "Cyclic","OnWrite","OnWriteWithRepetition","OnChange","OnChangeWithRepetition","IfActive","IfActiveWithRepetition","NoSigSendType";
BA_DEF_ SG_  "GenSigStartValue" FLOAT 0 0;
BA_DEF_ BO_  "CANFD_BRS" ENUM "0","1";
BA_DEF_ BU_  "NmStationAddress" INT 0 255;
BA_DEF_ BO_  "GenMsgSendType" ENUM "cyclic","Event Triggered","IfActive","NotUsed","NotUsed","NotUsed","NotUsed","NotUsed","noMsgSendType";
BA_DEF_ BO_  "GenMsgCycleTime" INT 0 3600000;
BA_DEF_  "DBName" STRING;
BA_DEF_  "ProtocolType" STRING;
BA_DEF_ BO_  "VFrameFormat" ENUM "StandardCAN","ExtendedCAN","reserved","J1939PG","reserved","reserved","reserved","reserved","reserved","reserved","reserved","reserved","reserved","reserved","StandardCAN_FD","ExtendedCAN_FD";
BA_DEF_  "SW_Version" FLOAT 0 0;
BA_DEF_  "Manufacturer" STRING;
BA_DEF_  "VersionNumber" FLOAT 0 0;
BA_DEF_  "VersionYear" INT 0 9999;
BA_DEF_  "VersionMonth" INT 1 12;
BA_DEF_  "BusType" STRING;
BA_DEF_  "Baudrate" INT 50000 500000;
BA_DEF_  "Arbitration_Baudrate" INT 0 0;

BA_DEF_DEF_  "ASIL" "NA";
BA_DEF_DEF_  "ASILLevel" "QM";
BA_DEF_DEF_  "Arbitration_Baudrate" 2000000;
BA_DEF_DEF_  "Baudrate" 100000;
BA_DEF_DEF_  "BusType" "CAN";
BA_DEF_DEF_  "CANFD_BRS" "0";
BA_DEF_DEF_  "GenMsgCycleTime" 0;
BA_DEF_DEF_  "GenMsgSendType" "noMsgSendType";
BA_DEF_DEF_  "GenSigSendType" "NoSigSendType";
BA_DEF_DEF_  "GenSigStartValue" 0.0;
BA_DEF_DEF_  "Manufacturer" "Holon People Mover";
BA_DEF_DEF_  "NmStationAddress" 254;
BA_DEF_DEF_  "ProtocolType" "J1939";
BA_DEF_DEF_  "SW_Version" 1.0;
BA_DEF_DEF_  "SigType" "Default";
BA_DEF_DEF_  "VFrameFormat" "J1939PG";
BA_DEF_DEF_  "VersionMonth" 1;
BA_DEF_DEF_  "VersionNumber" 0.0;
BA_DEF_DEF_  "VersionYear" 2006;

BA_ "Arbitration_Baudrate" 500000;
BA_ "Baudrate" 500000;
BA_ "BusType" "CAN 2.0B";
BA_ "DBName" "DCDC Pvt CAN";
BA_ "ProtocolType" "CAN 2.0B";
BA_ "SW_Version" 3.1;
BA_ "VersionMonth" 9;
BA_ "VersionNumber" 9;
BA_ "VersionYear" 2024;
BA_ "NmStationAddress" BU_ HV_PDU_1 25;
BA_ "NmStationAddress" BU_ VCU 16;
BA_ "GenMsgCycleTime" BO_ 10 20;
BA_ "GenMsgSendType" BO_ 10 0;
BA_ "VFrameFormat" BO_ 10 0;
BA_ "GenMsgCycleTime" BO_ 110 10;
BA_ "GenMsgSendType" BO_ 110 0;
BA_ "VFrameFormat" BO_ 110 0;
BA_ "GenMsgCycleTime" BO_ 111 10;
BA_ "GenMsgSendType" BO_ 111 0;
BA_ "VFrameFormat" BO_ 111 0;
BA_ "GenMsgCycleTime" BO_ 120 100;
BA_ "GenMsgSendType" BO_ 120 0;
BA_ "VFrameFormat" BO_ 120 0;
BA_ "GenMsgCycleTime" BO_ 150 500;
BA_ "GenMsgSendType" BO_ 150 0;
BA_ "VFrameFormat" BO_ 150 0;
BA_ "GenMsgCycleTime" BO_ 160 1000;
BA_ "GenMsgSendType" BO_ 160 0;
BA_ "VFrameFormat" BO_ 160 0;
BA_ "GenMsgCycleTime" BO_ 304 10;
BA_ "GenMsgSendType" BO_ 304 0;
BA_ "VFrameFormat" BO_ 304 0;
BA_ "VFrameFormat" BO_ 514 0;
BA_ "GenMsgCycleTime" BO_ 544 10;
BA_ "GenMsgSendType" BO_ 544 0;
BA_ "VFrameFormat" BO_ 544 0;
BA_ "VFrameFormat" BO_ 770 0;
BA_ "GenMsgCycleTime" BO_ 1024 100;
BA_ "GenMsgSendType" BO_ 1024 0;
BA_ "VFrameFormat" BO_ 1024 0;
BA_ "GenMsgCycleTime" BO_ 1040 100;
BA_ "GenMsgSendType" BO_ 1040 0;
BA_ "VFrameFormat" BO_ 1040 0;
BA_ "VFrameFormat" BO_ 1424 0;
BA_ "VFrameFormat" BO_ 1425 0;
BA_ "VFrameFormat" BO_ 1431 0;
BA_ "GenMsgCycleTime" BO_ 1757 1000;
BA_ "GenMsgSendType" BO_ 1757 0;
BA_ "VFrameFormat" BO_ 1757 0;
BA_ "GenMsgCycleTime" BO_ 1758 100;
BA_ "GenMsgSendType" BO_ 1758 0;
BA_ "VFrameFormat" BO_ 1758 0;
BA_ "GenMsgCycleTime" BO_ 1759 100;
BA_ "GenMsgSendType" BO_ 1759 0;
BA_ "VFrameFormat" BO_ 1759 0;
BA_ "GenMsgSendType" BO_ 1792 0;
BA_ "VFrameFormat" BO_ 1792 0;
BA_ "GenMsgSendType" BO_ 2015 0;
BA_ "VFrameFormat" BO_ 2015 0;
BA_ "GenMsgSendType" BO_ 2019 0;
BA_ "VFrameFormat" BO_ 2019 0;
BA_ "VFrameFormat" BO_ 2027 0;
BA_ "GenMsgCycleTime" BO_ 2147483904 10;
BA_ "GenMsgSendType" BO_ 2147483904 0;
BA_ "VFrameFormat" BO_ 2147483904 1;
BA_ "GenMsgCycleTime" BO_ 2147483905 10;
BA_ "GenMsgSendType" BO_ 2147483905 0;
BA_ "VFrameFormat" BO_ 2147483905 1;
BA_ "GenMsgCycleTime" BO_ 2147483906 10;
BA_ "GenMsgSendType" BO_ 2147483906 0;
BA_ "VFrameFormat" BO_ 2147483906 1;
BA_ "GenMsgCycleTime" BO_ 2147483907 10;
BA_ "GenMsgSendType" BO_ 2147483907 0;
BA_ "VFrameFormat" BO_ 2147483907 1;
BA_ "GenMsgCycleTime" BO_ 2147483908 1000;
BA_ "GenMsgSendType" BO_ 2147483908 0;
BA_ "VFrameFormat" BO_ 2147483908 1;
BA_ "GenMsgCycleTime" BO_ 2147483909 1000;
BA_ "GenMsgSendType" BO_ 2147483909 0;
BA_ "VFrameFormat" BO_ 2147483909 1;
BA_ "GenMsgCycleTime" BO_ 2147483910 1000;
BA_ "GenMsgSendType" BO_ 2147483910 0;
BA_ "VFrameFormat" BO_ 2147483910 1;
BA_ "GenMsgCycleTime" BO_ 2147483911 100;
BA_ "GenMsgSendType" BO_ 2147483911 0;
BA_ "VFrameFormat" BO_ 2147483911 1;
BA_ "ASIL" SG_ 10 Checksum_A 3;
BA_ "ASIL" SG_ 10 MessageCounter_A 3;
BA_ "ASIL" SG_ 10 PSM_CrashState_GW 3;
BA_ "ASIL" SG_ 110 Checksum_6E 3;
BA_ "ASIL" SG_ 110 MessageCounter_6E 3;
BA_ "ASIL" SG_ 110 BMS_Voltage 3;
BA_ "GenSigStartValue" SG_ 110 BMS_Voltage 4094;
BA_ "ASIL" SG_ 110 BMS_State 3;
BA_ "GenSigStartValue" SG_ 110 BMS_State 7;
BA_ "ASIL" SG_ 110 BMS_ContactorState 3;
BA_ "GenSigStartValue" SG_ 110 BMS_ContactorState 6;
BA_ "ASIL" SG_ 111 Checksum_6F 3;
BA_ "ASIL" SG_ 111 MessageCounter_6F 3;
BA_ "ASIL" SG_ 111 BMS_UCntct 3;
BA_ "GenSigStartValue" SG_ 111 BMS_UCntct 4094;
BA_ "ASIL" SG_ 120 Checksum_78 3;
BA_ "ASIL" SG_ 120 MessageCounter_78 3;
BA_ "ASIL" SG_ 120 BMS_MaxChgCurrLongTerm 3;
BA_ "GenSigStartValue" SG_ 120 BMS_MaxChgCurrLongTerm 4095;
BA_ "ASIL" SG_ 120 BMS_MaxChgCurrShortTerm 3;
BA_ "GenSigStartValue" SG_ 120 BMS_MaxChgCurrShortTerm 4095;
BA_ "ASIL" SG_ 150 Checksum_96 3;
BA_ "ASIL" SG_ 150 MessageCounter_96 3;
BA_ "ASIL" SG_ 150 BMS_MaxChgVoltage 3;
BA_ "GenSigStartValue" SG_ 150 BMS_MaxChgVoltage 1022;
BA_ "ASIL" SG_ 160 Checksum_A0 3;
BA_ "ASIL" SG_ 160 MessageCounter_A0 3;
BA_ "ASIL" SG_ 160 BMS_HVinterlockState 3;
BA_ "ASIL" SG_ 304 Checksum_130 3;
BA_ "ASIL" SG_ 304 MessageCounter_130 3;
BA_ "ASIL" SG_ 304 VCU_VoltageDemandHV 3;
BA_ "GenSigStartValue" SG_ 304 VCU_VoltageDemandHV 1022;
BA_ "ASIL" SG_ 304 VCU_CurrentLimitHV 3;
BA_ "GenSigStartValue" SG_ 304 VCU_CurrentLimitHV 2046;
BA_ "ASIL" SG_ 304 VCU_CurrentLimitLV 3;
BA_ "GenSigStartValue" SG_ 304 VCU_CurrentLimitLV 2046;
BA_ "ASIL" SG_ 304 VCU_VoltageDemandLV 3;
BA_ "GenSigStartValue" SG_ 304 VCU_VoltageDemandLV 510;
BA_ "ASIL" SG_ 304 VCU_ModeRequestDC 3;
BA_ "ASIL" SG_ 304 VCU_stT15DC 3;
BA_ "GenSigStartValue" SG_ 304 VCU_stT15DC 2;
BA_ "ASIL" SG_ 304 VCU_stHvDeactvnDC 3;
BA_ "ASIL" SG_ 544 Checksum_220 3;
BA_ "ASIL" SG_ 544 MessageCounter_220 3;
BA_ "ASIL" SG_ 544 DC1_VoltageHV 3;
BA_ "GenSigStartValue" SG_ 544 DC1_VoltageHV 1022;
BA_ "ASIL" SG_ 544 DC1_CurrentLV 3;
BA_ "GenSigStartValue" SG_ 544 DC1_CurrentLV 2046;
BA_ "ASIL" SG_ 544 DC1_Mode 3;
BA_ "GenSigStartValue" SG_ 544 DC1_Mode 6;
BA_ "ASIL" SG_ 544 DC1_CurrentHV 3;
BA_ "GenSigStartValue" SG_ 544 DC1_CurrentHV 2046;
BA_ "ASIL" SG_ 544 DC1_Temp 3;
BA_ "GenSigStartValue" SG_ 544 DC1_Temp 254;
BA_ "ASIL" SG_ 544 DC1_VoltageLV 3;
BA_ "GenSigStartValue" SG_ 544 DC1_VoltageLV 510;
BA_ "ASIL" SG_ 1024 Checksum_400 3;
BA_ "ASIL" SG_ 1024 MessageCounter_400 3;
BA_ "ASIL" SG_ 1024 DC1_MaxCurrentHV 3;
BA_ "ASIL" SG_ 1024 DC1_MaxCurrentLV 3;
BA_ "GenSigStartValue" SG_ 1024 DC1_MaxCurrentLV 1023;
BA_ "ASIL" SG_ 1024 DC1_SetPointVoltageHV 3;
BA_ "ASIL" SG_ 1024 DC1_SetPointVoltageLV 3;
BA_ "ASIL" SG_ 1024 DC1_Utilization 3;
BA_ "ASIL" SG_ 1040 Checksum_410 3;
BA_ "ASIL" SG_ 1040 MessageCounter_410 3;
BA_ "ASIL" SG_ 1040 DC1_bDernUndrUdcLv 3;
BA_ "ASIL" SG_ 1040 DC1_bDernOvrUdcLv 3;
BA_ "ASIL" SG_ 1040 DC1_bDernUndrUdcHv 3;
BA_ "ASIL" SG_ 1040 DC1_bDernOvrUdcHv 3;
BA_ "ASIL" SG_ 1040 DC1_bDernTemp_DCDC 3;
BA_ "ASIL" SG_ 1040 DC1_ErrLimitedPerformance 3;
BA_ "ASIL" SG_ 1040 DC1_bErrVltg 3;
BA_ "ASIL" SG_ 1040 DC1_ErrShtOff 3;
BA_ "ASIL" SG_ 1040 DC1_bErrCrashDetd 3;
BA_ "ASIL" SG_ 1040 DC1_bErrLvBattOutOfRng 3;
BA_ "ASIL" SG_ 1040 DC1_bErrHvLineOutOfRng 3;
BA_ "ASIL" SG_ 1040 DC1_bErrHvIllegalCurrent 3;
BA_ "ASIL" SG_ 1040 DC1_bErrHvSpNotReachedTimeout 3;
BA_ "ASIL" SG_ 1040 DC1_bErrCanMsg 3;
BA_ "ASIL" SG_ 1040 DC1_bPrecCmpl 3;
BA_ "ASIL" SG_ 1040 DC1_bReqMIL 3;
BA_ "ASIL" SG_ 1040 DC1_stT30c 3;
BA_ "GenSigStartValue" SG_ 1040 DC1_stT30c 2;
BA_ "GenSigStartValue" SG_ 1757 DIAG_Month 1;
BA_ "GenSigStartValue" SG_ 1757 DIAG_Day 1;
BA_ "GenSigStartValue" SG_ 1758 DIAG_VehicleSpeed 255;
BA_ "GenSigStartValue" SG_ 1758 DIAG_OutsideTemperature 254;
BA_ "GenSigStartValue" SG_ 1758 DIAG_AccelPdlPosn 255;
BA_ "GenSigStartValue" SG_ 1759 DIAG_AbsThrtlPos 255;
BA_ "GenSigStartValue" SG_ 1759 DIAG_EngLoad 255;
BA_ "GenSigStartValue" SG_ 1759 DIAG_EngCooltT 255;
BA_ "GenSigStartValue" SG_ 1759 DIAG_EngN 65534;
BA_ "ASIL" SG_ 2147483904 IVT_HVBattery_Crc 3;
BA_ "ASIL" SG_ 2147483904 IVT_HVBattery_MsgCnt 3;
BA_ "ASIL" SG_ 2147483904 IVT_Current 3;
BA_ "GenSigStartValue" SG_ 2147483904 IVT_Current 8388608;
BA_ "ASIL" SG_ 2147483904 IVT_Current_Status 3;
BA_ "GenSigStartValue" SG_ 2147483904 IVT_Current_Status 1;
BA_ "ASIL" SG_ 2147483904 IVT_HVBattery 3;
BA_ "GenSigStartValue" SG_ 2147483904 IVT_HVBattery 524288;
BA_ "ASIL" SG_ 2147483904 IVT_HVBattery_Status 3;
BA_ "GenSigStartValue" SG_ 2147483904 IVT_HVBattery_Status 1;
BA_ "ASIL" SG_ 2147483905 IVT_VoltageLink_Crc 3;
BA_ "ASIL" SG_ 2147483905 IVT_VoltageLink_MsgCnt 3;
BA_ "ASIL" SG_ 2147483905 IVT_VoltageLinkPlus 3;
BA_ "GenSigStartValue" SG_ 2147483905 IVT_VoltageLinkPlus 524288;
BA_ "ASIL" SG_ 2147483905 IVT_VoltageLinkPlus_Status 3;
BA_ "GenSigStartValue" SG_ 2147483905 IVT_VoltageLinkPlus_Status 1;
BA_ "ASIL" SG_ 2147483905 IVT_VoltageLinkMinus 3;
BA_ "GenSigStartValue" SG_ 2147483905 IVT_VoltageLinkMinus 524288;
BA_ "ASIL" SG_ 2147483905 IVT_VoltageLinkMinus_Status 3;
BA_ "GenSigStartValue" SG_ 2147483905 IVT_VoltageLinkMinus_Status 1;
BA_ "ASIL" SG_ 2147483906 IVT_VoltagePack_Crc 3;
BA_ "ASIL" SG_ 2147483906 IVT_VoltagePack_MsgCnt 3;
BA_ "ASIL" SG_ 2147483906 IVT_VoltagePackPlus 3;
BA_ "GenSigStartValue" SG_ 2147483906 IVT_VoltagePackPlus 524288;
BA_ "ASIL" SG_ 2147483906 IVT_VoltagePackPlus_Status 3;
BA_ "GenSigStartValue" SG_ 2147483906 IVT_VoltagePackPlus_Status 1;
BA_ "ASIL" SG_ 2147483906 IVT_VoltagePackMinus 3;
BA_ "GenSigStartValue" SG_ 2147483906 IVT_VoltagePackMinus 524288;
BA_ "ASIL" SG_ 2147483906 IVT_VoltagePackMinus_Status 3;
BA_ "GenSigStartValue" SG_ 2147483906 IVT_VoltagePackMinus_Status 1;
BA_ "ASIL" SG_ 2147483907 IVT_VoltageLinkPrChDiff_Crc 3;
BA_ "ASIL" SG_ 2147483907 IVT_VoltageLinkPrChDiff_MsgCnt 3;
BA_ "ASIL" SG_ 2147483907 IVT_VoltageLinkDiff 3;
BA_ "GenSigStartValue" SG_ 2147483907 IVT_VoltageLinkDiff 524288;
BA_ "ASIL" SG_ 2147483907 IVT_VoltageLinkDiff_Status 3;
BA_ "GenSigStartValue" SG_ 2147483907 IVT_VoltageLinkDiff_Status 1;
BA_ "ASIL" SG_ 2147483907 IVT_VoltageLinkPreCharge 3;
BA_ "GenSigStartValue" SG_ 2147483907 IVT_VoltageLinkPreCharge 524288;
BA_ "ASIL" SG_ 2147483907 IVT_VoltageLinkPreCharge_Status 3;
BA_ "GenSigStartValue" SG_ 2147483907 IVT_VoltageLinkPreCharge_Status 1;
BA_ "GenSigStartValue" SG_ 2147483908 IVT_IsoRes_Total_Status 1;
BA_ "GenSigStartValue" SG_ 2147483908 IVT_IsoRes_IsoMeasStatus 1;
BA_ "GenSigStartValue" SG_ 2147483909 IVT_IsoRes_HV_Pos_Status 1;
BA_ "GenSigStartValue" SG_ 2147483909 IVT_IsoRes_HV_Neg_Status 1;
BA_ "GenSigStartValue" SG_ 2147483910 IVT_IsoRes_Pack_Status 1;
BA_ "GenSigStartValue" SG_ 2147483910 IVT_IsoRes_Link_Status 1;
BA_ "GenSigStartValue" SG_ 2147483911 IVT_ShuntTemp 70;

VAL_ 10 Checksum_A 0 "Init";
VAL_ 10 MessageCounter_A 0 "Init";
VAL_ 10 PSM_CrashState_GW 0 "NoCrash" 1 "CrashSeverity1" 2 "CrashSeverity2" 3 "CrashSeverity3" 4 "CrashSeverity4" 5 "CrashSeverity5" 6 "CrashSeverity6" 7 "invalid value";
VAL_ 110 Checksum_6E 0 "Init";
VAL_ 110 MessageCounter_6E 0 "Init";
VAL_ 110 BMS_Voltage 4094 "Init" 4095 "Error";
VAL_ 110 BMS_State 0 "Standby" 1 "HVActive" 2 "Balancing" 3 "ExternalCharging" 4 "ExternalChargingHV" 5 "BatteryError" 6 "-" 7 "Initializing";
VAL_ 110 BMS_ContactorState 0 "HVBattCntctr_Open" 1 "HVBattCntctr_Closed" 2 "HVBattCntctr_SwitchingOn" 3 "HVBattCntctr_SwitchingOff" 4 "unused" 5 "unused" 6 "HVBattCntctr_Init" 7 "HVBattCntctr_Failure" 8 "unused" 9 "unused" 10 "unused" 11 "unused" 12 "unused" 13 "unused" 14 "unused" 15 "unused";
VAL_ 111 Checksum_6F 0 "Init";
VAL_ 111 MessageCounter_6F 0 "Init";
VAL_ 111 BMS_UCntct 4094 "Init" 4095 "Error";
VAL_ 120 MessageCounter_78 0 "Init";
VAL_ 120 BMS_MaxChgCurrLongTerm 4095 "Init";
VAL_ 120 BMS_MaxChgCurrShortTerm 4095 "Init";
VAL_ 150 Checksum_96 0 "Init";
VAL_ 150 MessageCounter_96 0 "Init";
VAL_ 150 BMS_MaxChgVoltage 1022 "Init" 1023 "Error";
VAL_ 160 Checksum_A0 0 "Init";
VAL_ 160 MessageCounter_A0 0 "Init";
VAL_ 160 BMS_HVinterlockState 0 "open" 1 "closed";
VAL_ 304 Checksum_130 0 "Init";
VAL_ 304 MessageCounter_130 0 "Init";
VAL_ 304 VCU_VoltageDemandHV 1022 "Init" 1023 "Error";
VAL_ 304 VCU_CurrentLimitHV 2046 "Init" 2047 "Error";
VAL_ 304 VCU_CurrentLimitLV 2046 "Init" 2047 "Error";
VAL_ 304 VCU_VoltageDemandLV 510 "Init" 511 "Error";
VAL_ 304 VCU_ModeRequestDC 0 "Standby" 1 "Buck" 2 "Boost" 3 "unused" 4 "Precharge" 5 "TestPls" 6 "unused" 7 "unused";
VAL_ 304 VCU_stT15DC 0 "T15 off" 1 "T15 on" 2 "init" 3 "error";
VAL_ 304 VCU_stHvDeactvnDC 0 "no deactivation of HV" 1 "HV deactivation" 2 "reserved" 3 "reserved";
VAL_ 544 Checksum_220 0 "Init";
VAL_ 544 MessageCounter_220 0 "Init";
VAL_ 544 DC1_VoltageHV 1022 "Init" 1023 "Failure";
VAL_ 544 DC1_CurrentLV 2046 "Init" 2047 "Failure";
VAL_ 544 DC1_Mode 0 "Standby" 1 "Buck" 2 "Boost" 3 "unused" 4 "Precharge" 5 "TestPls" 6 "Init" 7 "Failure";
VAL_ 544 DC1_CurrentHV 2046 "Init" 2047 "Failure";
VAL_ 544 DC1_Temp 254 "Init" 255 "Error";
VAL_ 544 DC1_VoltageLV 510 "Init" 511 "Failure";
VAL_ 1024 Checksum_400 0 "Init";
VAL_ 1024 MessageCounter_400 0 "Init";
VAL_ 1024 DC1_MaxCurrentHV 0 "Init";
VAL_ 1024 DC1_MaxCurrentLV 1023 "Init";
VAL_ 1024 DC1_SetPointVoltageHV 0 "Init";
VAL_ 1024 DC1_SetPointVoltageLV 0 "Init";
VAL_ 1024 DC1_Utilization 0 "Init";
VAL_ 1040 Checksum_410 0 "Init";
VAL_ 1040 MessageCounter_410 0 "Init";
VAL_ 1040 DC1_bPrecCmpl 0 "not completed" 1 "completed";
VAL_ 1040 DC1_bReqMIL 0 "MIL Off" 1 "MIL On";
VAL_ 1040 DC1_stT30c 0 "T30c off" 1 "T30c on" 2 "init" 3 "error";
VAL_ 1757 DIAG_Downtime_state 0 "not valid/calculated" 1 "valid";
VAL_ 1758 DIAG_VehicleSpeed 255 "Init";
VAL_ 1758 DIAG_OutsideTemperature 254 "Init" 255 "Failure";
VAL_ 1758 DIAG_EnvP_P 254 "not applicable" 255 "Error";
VAL_ 1758 DIAG_AccelPdlPosn 255 "Init";
VAL_ 1758 DIAG_flgPropSysActv 0 "No" 1 "Yes";
VAL_ 1758 DIAG_flgGnrlDenom 0 "No" 1 "Yes";
VAL_ 1758 DIAG_flgGnrlDenomInhbn 0 "No" 1 "Yes";
VAL_ 1758 DIAG_flgColdStrtDenom 0 "No" 1 "Yes";
VAL_ 1758 DIAG_flgColdStrtDenomInhbn 0 "No" 1 "Yes";
VAL_ 1758 DIAG_flgPDTCMinTrip 0 "No" 1 "Yes";
VAL_ 1758 DIAG_flgWarmUpCycle 0 "No" 1 "Yes";
VAL_ 1759 DIAG_AbsThrtlPos 255 "Init";
VAL_ 1759 DIAG_EngLoad 255 "Init";
VAL_ 1759 DIAG_EngCooltT 255 "Init";
VAL_ 1759 DIAG_EngN 65534 "Init" 65535 "Error";
VAL_ 2147483904 IVT_Current_Status 0 "Valid" 1 "Init" 2 "Overcurrent L1" 3 "Overcurrent L2" 4 "reserved4" 5 "reserved5" 6 "reserved6" 7 "reserved7" 8 "reserved8" 9 "reserved9" 10 "reserved10" 11 "reserved11" 12 "reserved12" 13 "reserved13" 14 "Not_Available" 15 "Error";
VAL_ 2147483904 IVT_HVBattery_Status 0 "Valid" 1 "Init" 2 "Overvoltage L1" 3 "Overvoltage L2" 4 "reserved4" 5 "reserved5" 6 "reserved6" 7 "reserved7" 8 "reserved8" 9 "reserved9" 10 "reserved10" 11 "reserved11" 12 "reserved12" 13 "reserved13" 14 "Not_Available" 15 "Error";
VAL_ 2147483905 IVT_VoltageLinkPlus_Status 0 "Valid" 1 "Init" 2 "Overvoltage L1" 3 "Overvoltage L2" 4 "reserved4" 5 "reserved5" 6 "reserved6" 7 "reserved7" 8 "reserved8" 9 "reserved9" 10 "reserved10" 11 "reserved11" 12 "reserved12" 13 "reserved13" 14 "Not_Available" 15 "Error";
VAL_ 2147483905 IVT_VoltageLinkMinus_Status 0 "Valid" 1 "Init" 2 "Overvoltage L1" 3 "Overvoltage L2" 4 "reserved4" 5 "reserved5" 6 "reserved6" 7 "reserved7" 8 "reserved8" 9 "reserved8" 10 "reserved10" 11 "reserved11" 12 "reserved12" 13 "reserved13" 14 "Not_Available" 15 "Error";
VAL_ 2147483906 IVT_VoltagePackPlus_Status 0 "Valid" 1 "Init" 2 "Overvoltage L1" 3 "Overvoltage L2" 4 "reserved4" 5 "reserved5" 6 "reserved6" 7 "reserved7" 8 "reserved8" 9 "reserved9" 10 "reserved10" 11 "reserved11" 12 "reserved12" 13 "reserved13" 14 "Not_Available" 15 "Error";
VAL_ 2147483906 IVT_VoltagePackMinus_Status 0 "Valid" 1 "Init" 2 "Overvoltage L1" 3 "Overvoltage L2" 4 "reserved4" 5 "reserved5" 6 "reserved6" 7 "reserved7" 8 "reserved8" 9 "reserved9" 10 "reserved10" 11 "reserved11" 12 "reserved12" 13 "reserved13" 14 "Not_Available" 15 "Error";
VAL_ 2147483907 IVT_VoltageLinkDiff_Status 0 "Valid" 1 "Init" 2 "Overvoltage L1" 3 "Overvoltage L2" 4 "reserved4" 5 "reserved5" 6 "reserved6" 7 "reserved7" 8 "reserved8" 9 "reserved9" 10 "reserved10" 11 "reserved11" 12 "reserved12" 13 "reserved13" 14 "Not_Available" 15 "Error";
VAL_ 2147483907 IVT_VoltageLinkPreCharge_Status 0 "Valid" 1 "Init" 2 "Overvoltage L1" 3 "Overvoltage L2" 4 "reserved4" 5 "reserved5" 6 "reserved6" 7 "reserved7" 8 "reserved8" 9 "reserved9" 10 "reserved10" 11 "reserved11" 12 "reserved12" 13 "reserved13" 14 "Not_Available" 15 "Error";
VAL_ 2147483908 IVT_IsoRes_Total_Status 0 "Valid" 1 "Init" 2 "Unqualified" 3 "reserved3" 4 "reserved4" 5 "reserved5" 6 "reserved6" 7 "reserved7" 8 "reserved8" 9 "reserved9" 10 "reserved10" 11 "reserved11" 12 "reserved12" 13 "reserved13" 14 "Not_Available" 15 "Error";
VAL_ 2147483908 IVT_IsoRes_IsoMeasStatus 0 "Disabled" 1 "Enabled";
VAL_ 2147483909 IVT_IsoRes_HV_Pos_Status 0 "Valid" 1 "Init" 2 "Unqualified" 3 "reserved3" 4 "reserved4" 5 "reserved5" 6 "reserved6" 7 "reserved7" 8 "reserved8" 9 "reserved9" 10 "reserved10" 11 "reserved11" 12 "reserved12" 13 "reserved13" 14 "Not_Available" 15 "Error";
VAL_ 2147483909 IVT_IsoRes_HV_Neg_Status 0 "Valid" 1 "Init" 2 "Unqualified" 3 "reserved3" 4 "reserved4" 5 "reserved5" 6 "reserved6" 7 "reserved7" 8 "reserved8" 9 "reserved9" 10 "reserved10" 11 "reserved11" 12 "reserved12" 13 "reserved13" 14 "Not_Available" 15 "Error";
VAL_ 2147483910 IVT_IsoRes_Pack_Status 0 "Valid" 1 "Init" 2 "Unqualified" 3 "reserved3" 4 "reserved4" 5 "reserved5" 6 "reserved6" 7 "reserved7" 8 "reserved8" 9 "reserved9" 10 "reserved10" 11 "reserved11" 12 "reserved12" 13 "reserved13" 14 "Not_Available" 15 "Error";
VAL_ 2147483910 IVT_IsoRes_Link_Status 0 "Valid" 1 "Init" 2 "Unqualified" 3 "reserved3" 4 "reserved4" 5 "reserved5" 6 "reserved6" 7 "reserved7" 8 "reserved8" 9 "reserved9" 10 "reserved10" 11 "reserved11" 12 "reserved12" 13 "reserved13" 14 "Not_Available" 15 "Error";
VAL_ 2147483911 IVT_ShuntTemp_Status 0 "Valid" 1 "Init" 2 "Overtemperature" 3 "Undertemperature" 4 "reserved4" 5 "reserved5" 6 "reserved6" 7 "reserved7" 8 "reserved8" 9 "reserved9" 10 "reserved10" 11 "reserved11" 12 "reserved12" 13 "reserved13" 14 "Not_Available" 15 "Error";

SIG_GROUP_  2147483904 IVT_HVBattery_I_V_group 1 : IVT_Current IVT_Current_Status IVT_HVBattery IVT_HVBattery_Crc IVT_HVBattery_MsgCnt IVT_HVBattery_Status;
SIG_GROUP_  2147483910 IVT_ISOResPackLink_group 1 : IVT_IsoResPackLink_Crc IVT_IsoResPackLink_MsgCnt IVT_IsoRes_Link IVT_IsoRes_Link_Status IVT_IsoRes_Pack IVT_IsoRes_Pack_Status;
SIG_GROUP_  2147483909 IVT_ISOResPosNeg_group 1 : IVT_ISOResPosNeg_Crc IVT_ISOResPosNeg_MsgCnt IVT_IsoRes_HV_Neg IVT_IsoRes_HV_Neg_Status IVT_IsoRes_HV_Pos IVT_IsoRes_HV_Pos_Status;
SIG_GROUP_  2147483908 IVT_ISOResTotal_group 1 : IVT_ISOResToal_Crc IVT_ISOResTotal_MsgCnt IVT_IsoRes_IsoMeasStatus IVT_IsoRes_Quality IVT_IsoRes_Total IVT_IsoRes_Total_Status;
SIG_GROUP_  2147483911 IVT_Temperature_group 1 : IVT_ShuntTemp IVT_ShuntTemp_Status;
SIG_GROUP_  2147483907 IVT_VoltLinkPreChDiff_group 1 : IVT_VoltageLinkDiff IVT_VoltageLinkDiff_Status IVT_VoltageLinkPrChDiff_Crc IVT_VoltageLinkPrChDiff_MsgCnt IVT_VoltageLinkPreCharge IVT_VoltageLinkPreCharge_Status;
SIG_GROUP_  2147483905 IVT_VoltageLink_group 1 : IVT_VoltageLinkMinus IVT_VoltageLinkMinus_Status IVT_VoltageLinkPlus IVT_VoltageLinkPlus_Status IVT_VoltageLink_Crc IVT_VoltageLink_MsgCnt;
SIG_GROUP_  2147483906 IVT_VoltagePack_group 1 : IVT_VoltagePackMinus IVT_VoltagePackMinus_Status IVT_VoltagePackPlus IVT_VoltagePackPlus_Status IVT_VoltagePack_Crc IVT_VoltagePack_MsgCnt;
